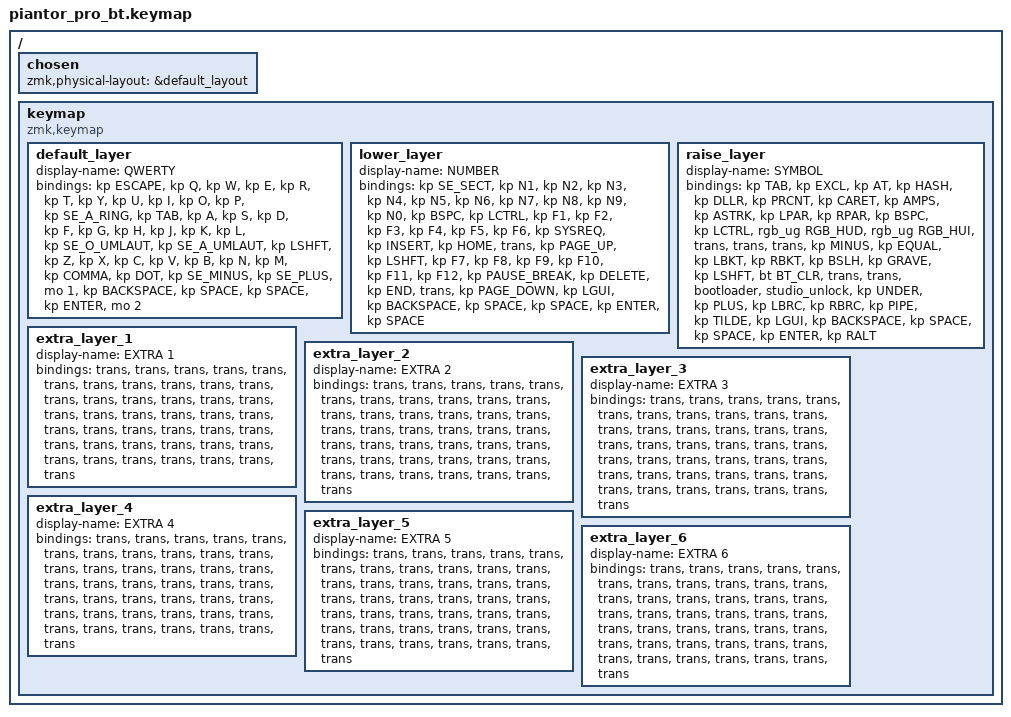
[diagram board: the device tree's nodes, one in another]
/*
 * Copyright (c) 2020 The ZMK Contributors
 *
 * SPDX-License-Identifier: MIT
 */

#include <behaviors.dtsi>
#include <dt-bindings/zmk/bt.h>
#include <dt-bindings/zmk/keys.h>
#include <dt-bindings/zmk/rgb.h>
#include "keys_se.h"

/ {
    chosen { zmk,physical-layout = &default_layout; };
};

/ {
    keymap {
        compatible = "zmk,keymap";

        default_layer {
            display-name = "QWERTY";

            // --------------------------------------------------------------------------------
            // |  TAB |  Q  |  W  |  E  |  R  |  T  |  Y  |  U   |  I  |  O  |  P  | BSPC |
            // | CTRL |  A  |  S  |  D  |  F  |  G  |  H  |  J   |  K  |  L  |  ;  |  '   |
            // | SHFT |  Z  |  X  |  C  |  V  |  B  |  N  |  M   |  ,  |  .  |  /  | ESC  |
            //                    | GUI | LWR | SPC | ENT | RSE  | ALT |

            bindings = <
&kp ESCAPE  &kp Q  &kp W  &kp E  &kp R  &kp T  &kp Y  &kp U  &kp I  &kp O  &kp P  &kp SE_A_RING  &kp TAB  &kp A  &kp S  &kp D  &kp F  &kp G  &kp H  &kp J  &kp K  &kp L  &kp SE_O_UMLAUT  &kp SE_A_UMLAUT  &kp LSHFT  &kp Z  &kp X  &kp C  &kp V  &kp B  &kp N  &kp M  &kp COMMA  &kp DOT  &kp SE_MINUS  &kp SE_PLUS  &mo 1  &kp BACKSPACE  &kp SPACE  &kp SPACE  &kp ENTER  &mo 2
            >;
        };

        lower_layer {
            display-name = "NUMBER";

            // -----------------------------------------------------------------------------------------
            // |  TAB |  1  |  2  |  3  |  4  |  5    |  6  |  7  |  8  |  9  |  0  | BSPC |
            // | CTRL | BT1 | BT2 | BT3 | BT4 | BT5   | LFT | DWN |  UP | RGT |     |      |
            // | SHFT | BTCR| RGB | RST | BOOT| Unlock|     |     |     |     |     |      |
            //                    | GUI |     | SPC   | ENT |     | ALT |

            bindings = <
&kp SE_SECT  &kp N1  &kp N2  &kp N3  &kp N4  &kp N5  &kp N6  &kp N7  &kp N8  &kp N9  &kp N0  &kp BSPC  &kp LCTRL  &kp F1  &kp F2  &kp F3  &kp F4  &kp F5  &kp F6  &kp SYSREQ  &kp INSERT  &kp HOME  &trans  &kp PAGE_UP  &kp LSHFT  &kp F7  &kp F8  &kp F9  &kp F10  &kp F11  &kp F12  &kp PAUSE_BREAK  &kp DELETE  &kp END  &trans  &kp PAGE_DOWN  &kp LGUI  &kp BACKSPACE  &kp SPACE  &kp SPACE  &kp ENTER  &kp SPACE
            >;
        };

        raise_layer {
            display-name = "SYMBOL";

            // -----------------------------------------------------------------------------------------
            // |  TAB |  !  |  @  |  #  |  $  |  %  |  ^  |  &  |  *  |  (  |  )  | BSPC |
            // | CTRL | HUD | HUI |     |     |     |  -  |  =  |  [  |  ]  |  \  |  `   |
            // | SHFT |     |     |     |     |     |  _  |  +  |  {  |  }  | "|" |  ~   |
            //                    | GUI |     | SPC | ENT |     | ALT |

            bindings = <
&kp TAB  &kp EXCL  &kp AT  &kp HASH  &kp DLLR  &kp PRCNT  &kp CARET  &kp AMPS  &kp ASTRK  &kp LPAR  &kp RPAR  &kp BSPC  &kp LCTRL  &rgb_ug RGB_HUD  &rgb_ug RGB_HUI  &trans  &trans  &trans  &kp MINUS  &kp EQUAL  &kp LBKT  &kp RBKT  &kp BSLH  &kp GRAVE  &kp LSHFT  &bt BT_CLR  &trans  &trans  &bootloader  &studio_unlock  &kp UNDER  &kp PLUS  &kp LBRC  &kp RBRC  &kp PIPE  &kp TILDE  &kp LGUI  &kp BACKSPACE  &kp SPACE  &kp SPACE  &kp ENTER  &kp RALT
            >;
        };

        extra_layer_1 {
            display-name = "EXTRA 1";
            bindings = <
&trans  &trans  &trans  &trans  &trans  &trans  &trans  &trans  &trans  &trans  &trans  &trans  &trans  &trans  &trans  &trans  &trans  &trans  &trans  &trans  &trans  &trans  &trans  &trans  &trans  &trans  &trans  &trans  &trans  &trans  &trans  &trans  &trans  &trans  &trans  &trans  &trans  &trans  &trans  &trans  &trans  &trans
            >;
        };

        extra_layer_2 {
            display-name = "EXTRA 2";
            bindings = <
&trans  &trans  &trans  &trans  &trans  &trans  &trans  &trans  &trans  &trans  &trans  &trans  &trans  &trans  &trans  &trans  &trans  &trans  &trans  &trans  &trans  &trans  &trans  &trans  &trans  &trans  &trans  &trans  &trans  &trans  &trans  &trans  &trans  &trans  &trans  &trans  &trans  &trans  &trans  &trans  &trans  &trans
            >;
        };

        extra_layer_3 {
            display-name = "EXTRA 3";
            bindings = <
&trans  &trans  &trans  &trans  &trans  &trans  &trans  &trans  &trans  &trans  &trans  &trans  &trans  &trans  &trans  &trans  &trans  &trans  &trans  &trans  &trans  &trans  &trans  &trans  &trans  &trans  &trans  &trans  &trans  &trans  &trans  &trans  &trans  &trans  &trans  &trans  &trans  &trans  &trans  &trans  &trans  &trans
            >;
        };

        extra_layer_4 {
            display-name = "EXTRA 4";
            bindings = <
&trans  &trans  &trans  &trans  &trans  &trans  &trans  &trans  &trans  &trans  &trans  &trans  &trans  &trans  &trans  &trans  &trans  &trans  &trans  &trans  &trans  &trans  &trans  &trans  &trans  &trans  &trans  &trans  &trans  &trans  &trans  &trans  &trans  &trans  &trans  &trans  &trans  &trans  &trans  &trans  &trans  &trans
            >;
        };

        extra_layer_5 {
            display-name = "EXTRA 5";
            bindings = <
&trans  &trans  &trans  &trans  &trans  &trans  &trans  &trans  &trans  &trans  &trans  &trans  &trans  &trans  &trans  &trans  &trans  &trans  &trans  &trans  &trans  &trans  &trans  &trans  &trans  &trans  &trans  &trans  &trans  &trans  &trans  &trans  &trans  &trans  &trans  &trans  &trans  &trans  &trans  &trans  &trans  &trans
            >;
        };

        extra_layer_6 {
            display-name = "EXTRA 6";
            bindings = <
&trans  &trans  &trans  &trans  &trans  &trans  &trans  &trans  &trans  &trans  &trans  &trans  &trans  &trans  &trans  &trans  &trans  &trans  &trans  &trans  &trans  &trans  &trans  &trans  &trans  &trans  &trans  &trans  &trans  &trans  &trans  &trans  &trans  &trans  &trans  &trans  &trans  &trans  &trans  &trans  &trans  &trans
            >;
        };
    };
};
